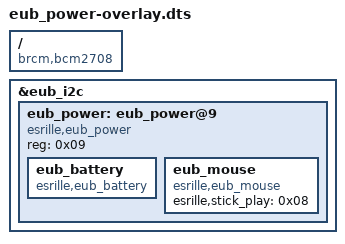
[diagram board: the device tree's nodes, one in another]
// Definitions for Esrille Unbrick Power Board Multi-Function Driver
/dts-v1/;
/plugin/;

/ {
	compatible = "brcm,bcm2708";

	fragment@0 {
		target = <&eub_i2c>;
		__overlay__ {
			#address-cells = <1>;
			#size-cells = <0>;
			status = "okay";

			eub_power: eub_power@9 {
				compatible = "esrille,eub_power";
				reg = <0x09>;
				status = "okay";
				eub_battery: eub_battery {
					compatible = "esrille,eub_battery";
				};
				eub_mouse: eub_mouse {
					compatible = "esrille,eub_mouse";
					esrille,stick_play = /bits/ 8 <0x08>;
				};
			};
		};
	};
	__overrides__ {
		addr = <&eub_power>, "reg:0";
		stick_play = <&eub_mouse>,"esrille,stick_play.0";
	};
};

